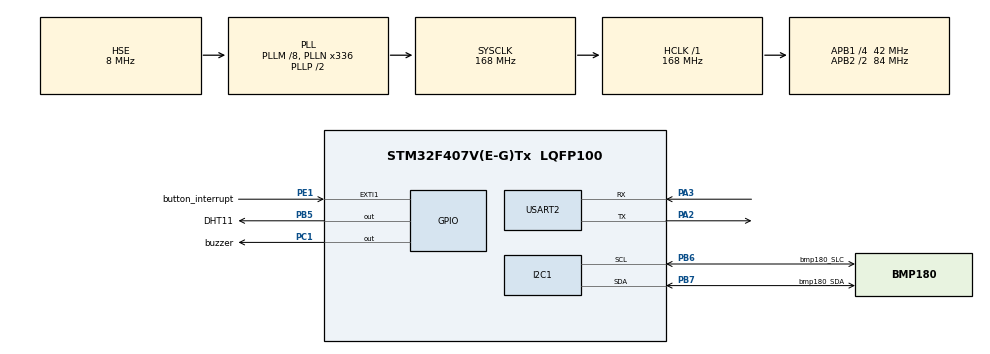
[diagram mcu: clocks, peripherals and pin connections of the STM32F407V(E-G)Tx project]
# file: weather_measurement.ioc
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Mcu.Family=STM32F4
Mcu.Name=STM32F407V(E-G)Tx
Mcu.Package=LQFP100
NVIC.EXTI1_IRQn=true\:0\:0\:false\:false\:true\:true\:true\:true
NVIC.PriorityGroup=NVIC_PRIORITYGROUP_0
NVIC.TIM7_IRQn=true\:0\:0\:false\:false\:true\:true\:true\:true
PA2.Mode=Asynchronous
PA2.Signal=USART2_TX
PA3.Mode=Asynchronous
PA3.Signal=USART2_RX
PB5.GPIO_Label=DHT11
PB5.GPIO_PuPd=GPIO_PULLUP
PB5.GPIO_Speed=GPIO_SPEED_FREQ_HIGH
PB5.PinState=GPIO_PIN_RESET
PB5.Signal=GPIO_Output
PB6.GPIO_Label=bmp180_SLC
PB6.Mode=I2C
PB6.Signal=I2C1_SCL
PB7.GPIO_Label=bmp180_SDA
PB7.Mode=I2C
PB7.Signal=I2C1_SDA
PC1.GPIO_Label=buzzer
PC1.Signal=GPIO_Output
PC14-OSC32_IN.Mode=LSE-External-Oscillator
PC14-OSC32_IN.Signal=RCC_OSC32_IN
PC15-OSC32_OUT.Mode=LSE-External-Oscillator
PC15-OSC32_OUT.Signal=RCC_OSC32_OUT
PE1.GPIO_Label=button_interrupt
PE1.GPIO_ModeDefaultEXTI=GPIO_MODE_IT_RISING
PE1.Signal=GPXTI1
PH0-OSC_IN.Mode=HSE-External-Oscillator
PH0-OSC_IN.Signal=RCC_OSC_IN
PH1-OSC_OUT.Mode=HSE-External-Oscillator
PH1-OSC_OUT.Signal=RCC_OSC_OUT
ProjectManager.HeapSize=0x200
ProjectManager.StackSize=0x400
ProjectManager.TargetToolchain=STM32CubeIDE
RCC.48MHZClocksFreq_Value=48000000
RCC.AHBFreq_Value=168000000
RCC.APB1CLKDivider=RCC_HCLK_DIV4
RCC.APB1Freq_Value=42000000
RCC.APB1TimFreq_Value=84000000
RCC.APB2CLKDivider=RCC_HCLK_DIV2
RCC.APB2Freq_Value=84000000
RCC.APB2TimFreq_Value=168000000
RCC.CortexFreq_Value=168000000
RCC.HCLKFreq_Value=168000000
RCC.HSE_VALUE=8000000
RCC.HSI_VALUE=16000000
RCC.PLLM=8
RCC.PLLN=336
RCC.PLLQ=7
RCC.PLLSourceVirtual=RCC_PLLSOURCE_HSE
RCC.SYSCLKFreq_VALUE=168000000
RCC.SYSCLKSource=RCC_SYSCLKSOURCE_PLLCLK
RCC.VCOOutputFreq_Value=336000000
TIM6.Prescaler=83
TIM7.AutoReloadPreload=TIM_AUTORELOAD_PRELOAD_ENABLE
TIM7.Period=60000
TIM7.Prescaler=45000
USART2.VirtualMode=VM_ASYNC
VP_TIM6_VS_ClockSourceINT.Mode=Enable_Timer
VP_TIM7_VS_ClockSourceINT.Mode=Enable_Timer
board=STM32F407G-DISC1

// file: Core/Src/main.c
/* USER CODE BEGIN Header */
/**
  ******************************************************************************
  * @file           : main.c
  * @brief          : Main program body
  ******************************************************************************
  * @attention
  *
  * Copyright (c) 2023 STMicroelectronics.
  * All rights reserved.
  *
  * This software is licensed under terms that can be found in the LICENSE file
  * in the root directory of this software component.
  * If no LICENSE file comes with this software, it is provided AS-IS.
  *
  ******************************************************************************
  */
/* USER CODE END Header */
#include "main.h"
#include "bmp180.h"

I2C_HandleTypeDef hi2c1;

TIM_HandleTypeDef htim6;
TIM_HandleTypeDef htim7;

UART_HandleTypeDef huart2;

void SystemClock_Config(void);
static void MX_GPIO_Init(void);
static void MX_I2C1_Init(void);
static void MX_TIM6_Init(void);
static void MX_TIM7_Init(void);
static void MX_USART2_UART_Init(void);
/* USER CODE BEGIN PFP */
float my_temperature = 0;
float my_pressure = 0;
float altitude = 0;
/* USER CODE END PFP */

/* USER CODE BEGIN 0 */
void tx_json_data(float temp, float press, float alt);
/* USER CODE END 0 */

int main(void)
{

  /* MCU Configuration--------------------------------------------------------*/

  /* Reset of all peripherals, Initializes the Flash interface and the Systick. */
  HAL_Init();

  /* Configure the system clock */
  SystemClock_Config();

  /* Initialize all configured peripherals */
  MX_GPIO_Init();
  MX_I2C1_Init();
  MX_TIM6_Init();
  MX_TIM7_Init();
  MX_USART2_UART_Init();
  /* USER CODE BEGIN 2 */
  bmp180_init();
  /* USER CODE END 2 */

  /* Infinite loop */
  while (1)
  {
	  my_temperature = bmp180_read_temperature();
	  my_pressure = bmp180_read_pressure(1);
	  altitude = bmp180_read_altitude(1);

	  HAL_Delay(2000);

	  tx_json_data(my_temperature, my_pressure, altitude);
  }
}

void SystemClock_Config(void)
{
  RCC_OscInitTypeDef RCC_OscInitStruct = {0};
  RCC_ClkInitTypeDef RCC_ClkInitStruct = {0};

  /** Configure the main internal regulator output voltage
  */
  __HAL_RCC_PWR_CLK_ENABLE();
  __HAL_PWR_VOLTAGESCALING_CONFIG(PWR_REGULATOR_VOLTAGE_SCALE1);

  /** Initializes the RCC Oscillators according to the specified parameters
  * in the RCC_OscInitTypeDef structure.
  */
  RCC_OscInitStruct.OscillatorType = RCC_OSCILLATORTYPE_HSE;
  RCC_OscInitStruct.HSEState = RCC_HSE_ON;
  RCC_OscInitStruct.PLL.PLLState = RCC_PLL_ON;
  RCC_OscInitStruct.PLL.PLLSource = RCC_PLLSOURCE_HSE;
  RCC_OscInitStruct.PLL.PLLM = 8;
  RCC_OscInitStruct.PLL.PLLN = 336;
  RCC_OscInitStruct.PLL.PLLP = RCC_PLLP_DIV2;
  RCC_OscInitStruct.PLL.PLLQ = 7;
  if (HAL_RCC_OscConfig(&RCC_OscInitStruct) != HAL_OK)
  {
    Error_Handler();
  }

  /** Initializes the CPU, AHB and APB buses clocks
  */
  RCC_ClkInitStruct.ClockType = RCC_CLOCKTYPE_HCLK|RCC_CLOCKTYPE_SYSCLK
                              |RCC_CLOCKTYPE_PCLK1|RCC_CLOCKTYPE_PCLK2;
  RCC_ClkInitStruct.SYSCLKSource = RCC_SYSCLKSOURCE_PLLCLK;
  RCC_ClkInitStruct.AHBCLKDivider = RCC_SYSCLK_DIV1;
  RCC_ClkInitStruct.APB1CLKDivider = RCC_HCLK_DIV4;
  RCC_ClkInitStruct.APB2CLKDivider = RCC_HCLK_DIV2;

  if (HAL_RCC_ClockConfig(&RCC_ClkInitStruct, FLASH_LATENCY_5) != HAL_OK)
  {
    Error_Handler();
  }
}

static void MX_I2C1_Init(void)
{

  hi2c1.Instance = I2C1;
  hi2c1.Init.ClockSpeed = 100000;
  hi2c1.Init.DutyCycle = I2C_DUTYCYCLE_2;
  hi2c1.Init.OwnAddress1 = 0;
  hi2c1.Init.AddressingMode = I2C_ADDRESSINGMODE_7BIT;
  hi2c1.Init.DualAddressMode = I2C_DUALADDRESS_DISABLE;
  hi2c1.Init.OwnAddress2 = 0;
  hi2c1.Init.GeneralCallMode = I2C_GENERALCALL_DISABLE;
  hi2c1.Init.NoStretchMode = I2C_NOSTRETCH_DISABLE;
  if (HAL_I2C_Init(&hi2c1) != HAL_OK)
  {
    Error_Handler();
  }

}

static void MX_TIM6_Init(void)
{

  TIM_MasterConfigTypeDef sMasterConfig = {0};

  htim6.Instance = TIM6;
  htim6.Init.Prescaler = 83;
  htim6.Init.CounterMode = TIM_COUNTERMODE_UP;
  htim6.Init.Period = 65535;
  htim6.Init.AutoReloadPreload = TIM_AUTORELOAD_PRELOAD_DISABLE;
  if (HAL_TIM_Base_Init(&htim6) != HAL_OK)
  {
    Error_Handler();
  }
  sMasterConfig.MasterOutputTrigger = TIM_TRGO_RESET;
  sMasterConfig.MasterSlaveMode = TIM_MASTERSLAVEMODE_DISABLE;
  if (HAL_TIMEx_MasterConfigSynchronization(&htim6, &sMasterConfig) != HAL_OK)
  {
    Error_Handler();
  }

}

static void MX_TIM7_Init(void)
{

  TIM_MasterConfigTypeDef sMasterConfig = {0};

  htim7.Instance = TIM7;
  htim7.Init.Prescaler = 65535;
  htim7.Init.CounterMode = TIM_COUNTERMODE_UP;
  htim7.Init.Period = 65535;
  htim7.Init.AutoReloadPreload = TIM_AUTORELOAD_PRELOAD_DISABLE;
  if (HAL_TIM_Base_Init(&htim7) != HAL_OK)
  {
    Error_Handler();
  }
  sMasterConfig.MasterOutputTrigger = TIM_TRGO_RESET;
  sMasterConfig.MasterSlaveMode = TIM_MASTERSLAVEMODE_DISABLE;
  if (HAL_TIMEx_MasterConfigSynchronization(&htim7, &sMasterConfig) != HAL_OK)
  {
    Error_Handler();
  }

}

static void MX_USART2_UART_Init(void)
{

  huart2.Instance = USART2;
  huart2.Init.BaudRate = 115200;
  huart2.Init.WordLength = UART_WORDLENGTH_8B;
  huart2.Init.StopBits = UART_STOPBITS_1;
  huart2.Init.Parity = UART_PARITY_NONE;
  huart2.Init.Mode = UART_MODE_TX_RX;
  huart2.Init.HwFlowCtl = UART_HWCONTROL_NONE;
  huart2.Init.OverSampling = UART_OVERSAMPLING_16;
  if (HAL_UART_Init(&huart2) != HAL_OK)
  {
    Error_Handler();
  }

}

static void MX_GPIO_Init(void)
{
  GPIO_InitTypeDef GPIO_InitStruct = {0};

  /* GPIO Ports Clock Enable */
  __HAL_RCC_GPIOC_CLK_ENABLE();
  __HAL_RCC_GPIOH_CLK_ENABLE();
  __HAL_RCC_GPIOA_CLK_ENABLE();
  __HAL_RCC_GPIOB_CLK_ENABLE();
  __HAL_RCC_GPIOE_CLK_ENABLE();

  /*Configure GPIO pin Output Level */
  HAL_GPIO_WritePin(buzzer_GPIO_Port, buzzer_Pin, GPIO_PIN_RESET);

  /*Configure GPIO pin Output Level */
  HAL_GPIO_WritePin(dht11_GPIO_Port, dht11_Pin, GPIO_PIN_RESET);

  /*Configure GPIO pin : buzzer_Pin */
  GPIO_InitStruct.Pin = buzzer_Pin;
  GPIO_InitStruct.Mode = GPIO_MODE_OUTPUT_PP;
  GPIO_InitStruct.Pull = GPIO_NOPULL;
  GPIO_InitStruct.Speed = GPIO_SPEED_FREQ_LOW;
  HAL_GPIO_Init(buzzer_GPIO_Port, &GPIO_InitStruct);

  /*Configure GPIO pin : dht11_Pin */
  GPIO_InitStruct.Pin = dht11_Pin;
  GPIO_InitStruct.Mode = GPIO_MODE_OUTPUT_PP;
  GPIO_InitStruct.Pull = GPIO_NOPULL;
  GPIO_InitStruct.Speed = GPIO_SPEED_FREQ_LOW;
  HAL_GPIO_Init(dht11_GPIO_Port, &GPIO_InitStruct);

  /*Configure GPIO pin : button_interrupt_Pin */
  GPIO_InitStruct.Pin = button_interrupt_Pin;
  GPIO_InitStruct.Mode = GPIO_MODE_IT_RISING;
  GPIO_InitStruct.Pull = GPIO_NOPULL;
  HAL_GPIO_Init(button_interrupt_GPIO_Port, &GPIO_InitStruct);

}

/* USER CODE BEGIN 4 */
/*
 * TODO: 1) fix warnings
 * 		 2) complete the function
 * 		 3) add timer to send datas automatically
 * 		 4)
 * */

void tx_json_data(float temp, float press, float alt)
{
	char json_buff[100] = "";

	sprintf(json_buff,	"{ \"temp\" : \"%.2f\", \"press\": \"%.2f\", \"alt\" : \"%.2f\" }", temp, press, alt);
    strcat(json_buff, "\0");

	HAL_UART_Transmit(&huart2, (uint8_t*)json_buff, strlen(json_buff), HAL_MAX_DELAY);

}
/* USER CODE END 4 */

void Error_Handler(void)
{
  __disable_irq();
  while (1)
  {
  }
}
